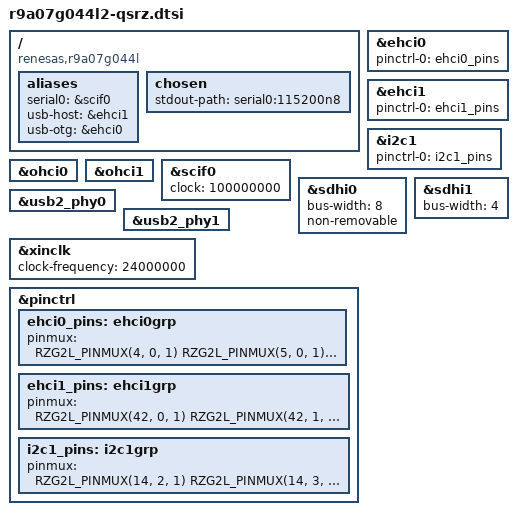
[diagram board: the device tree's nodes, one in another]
// SPDX-License-Identifier: (GPL-2.0-only OR BSD-3-Clause)
/*
 * Device Tree Source for the Ka-Ro G2L based QSRZ CoM
 *
 * Copyright (C) 2023 Markus Bauer <mb@karo-electronics.com>
 */

#include <dt-bindings/gpio/gpio.h>
#include <dt-bindings/pinctrl/rzg2l-pinctrl.h>
#include "r9a07g044l.dtsi"

/ {
	compatible = "renesas,r9a07g044l", "renesas,rzg2l";

	aliases {
		serial0 = &scif0;
		usb-host = &ehci1;
		usb-otg = &ehci0;
	};

	chosen {
		stdout-path = "serial0:115200n8";
	};
};

&ehci0 {
	pinctrl-names = "default";
	pinctrl-0 = <&ehci0_pins>;
	status = "okay";
};

&ehci1 {
	pinctrl-names = "default";
	pinctrl-0 = <&ehci1_pins>;
	status = "okay";
};

&i2c1 {
	pinctrl-names = "default";
	pinctrl-0 = <&i2c1_pins>;
	status = "okay";
};

&ohci0 {
	status = "okay";
};

&ohci1 {
	status = "okay";
};

&scif0 {
	status = "okay";
	clock = <100000000>;
};

&sdhi0 {
	bus-width = <8>;
	non-removable;
	status = "okay";
};

&sdhi1 {
	bus-width = <4>;
	status = "okay";
};

&usb2_phy0 {
	status = "okay";
};

&usb2_phy1 {
	status = "okay";
};

&xinclk {
        clock-frequency = <24000000>;
};

&pinctrl {
	ehci0_pins: ehci0grp {
		pinmux = <
			  RZG2L_PINMUX(4, 0, 1)
			  RZG2L_PINMUX(5, 0, 1)
			  RZG2L_PINMUX(5, 1, 1)
		>;
	};

	ehci1_pins: ehci1grp {
		pinmux = <
			  RZG2L_PINMUX(42, 0, 1)
			  RZG2L_PINMUX(42, 1, 1)
		>;
	};

	i2c1_pins: i2c1grp {
		pinmux = <
			  RZG2L_PINMUX(14, 2, 1)
			  RZG2L_PINMUX(14, 3, 1)
		>;
	};
};
